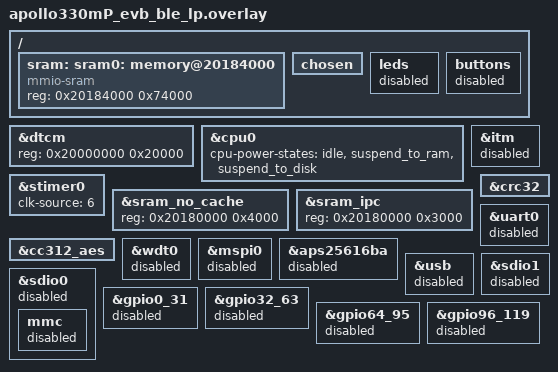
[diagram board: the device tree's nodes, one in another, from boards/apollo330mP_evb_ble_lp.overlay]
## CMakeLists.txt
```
# Copyright (c) 2026, Ambiq Micro Inc. <www.ambiq.com>
# SPDX-License-Identifier: Apache-2.0

cmake_minimum_required(VERSION 3.20.0)

find_package(Zephyr REQUIRED HINTS $ENV{ZEPHYR_BASE})

project(pm_peripheral_demo)

target_sources(app PRIVATE src/main.c)
```

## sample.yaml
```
sample:
  name: PM Peripheral Demo

tests:
  sample.boards.ambiq.pm_peripheral_demo:
    platform_allow:
      - apollo330mP_evb
      - apollo510dL_evb
    tags:
      - pm
      - bluetooth
      - flash
      - spi
      - i2c
      - crc
      - crypto
```

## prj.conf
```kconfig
# Logging
CONFIG_LOG=y

# BLE
CONFIG_BT=y
CONFIG_BT_PERIPHERAL=y
CONFIG_BT_DEVICE_NAME="Ambiq PM Demo"

# Flash
CONFIG_FLASH=y
CONFIG_FLASH_MAP=y

# SPI
CONFIG_SPI=y

# I2C
CONFIG_I2C=y

# Entropy (TRNG via zephyr,entropy = &trng in board chosen)
CONFIG_ENTROPY_GENERATOR=y

# CRC (hardware driver)
CONFIG_CRC=y

# Crypto (hardware CC312 AES via ambiq,crypto-aes DT node; driver auto-selected)
CONFIG_CRYPTO=y

# PM (already in board defconfig; kept here for portability)
CONFIG_PM=y
CONFIG_PM_DEVICE=y
CONFIG_PM_DEVICE_RUNTIME=y

CONFIG_MAIN_STACK_SIZE=4096
```

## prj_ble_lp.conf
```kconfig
CONFIG_BT=y
CONFIG_BT_SMP=y
CONFIG_BT_PERIPHERAL=y
CONFIG_BT_DIS=y
CONFIG_BT_DIS_PNP=n
CONFIG_BT_BAS=y
CONFIG_BT_HRS=y

CONFIG_BT_DEVICE_NAME="Ambiq PM Demo"
CONFIG_BT_DEVICE_APPEARANCE=833

# Recommended LP advertising interval for test setup.
# These preferred connection parameters reduce connected-mode radio wakeups.
CONFIG_BT_PERIPHERAL_PREF_MIN_INT=400
CONFIG_BT_PERIPHERAL_PREF_MAX_INT=480
CONFIG_BT_PERIPHERAL_PREF_LATENCY=4
CONFIG_BT_PERIPHERAL_PREF_TIMEOUT=3200

# CEVA/RSS 510L: RF trim IPC + RSS opmode + HCI 0xFC80 NVDS sleep + VS 0xFC82/0xFC83,
# then host HCI_Reset (see apollox_ipc_support.c).

# Match AmbiqSuite ble_freertos_fit_lp early SoC init (LFRC RTC, XTAL deepsleep, SRAM 0.75M retain,
# caches off, IOSFD..NETAOL-1 gating, NETAOL/RSS on). See CONFIG_SOC_AMBIQ_APOLLO5X_BLE_LP in soc/Kconfig.
# Enabling this option will further reduce power consumption in sleep modes, but with risk of stability.
# Disable this option if user experience stability issues.
CONFIG_SOC_AMBIQ_APOLLO5X_BLE_LP=y

CONFIG_LOG=n
CONFIG_BOOT_BANNER=n
CONFIG_PRINTK=n
CONFIG_EARLY_CONSOLE=n
CONFIG_CONSOLE=n
CONFIG_UART_CONSOLE=n

# Keep Ambiq HAL GPIO available for SoC clock code without enabling the sample LED path.
CONFIG_PINCTRL=y
CONFIG_GPIO=n
CONFIG_SPI=n
CONFIG_I2C=n
CONFIG_WATCHDOG=n

# Enable CRC32 hardware accelerator.
CONFIG_CRC=y

# Demo threads exercise storage_partition through Zephyr's flash map API.
CONFIG_FLASH=y
CONFIG_FLASH_MAP=y

# Enable entropy/TRNG for random number generation.
CONFIG_ENTROPY_GENERATOR=y

# Demo AES thread uses the Ambiq CC312 AES crypto device.
CONFIG_CRYPTO=y

CONFIG_PM=y
CONFIG_PM_DEVICE=y
CONFIG_PM_DEVICE_RUNTIME=y
CONFIG_PM_NEED_ALL_DEVICES_IDLE=y

# CPU idle: long timer slips + default policy choose suspend-to-idle / suspend-to-ram from DT.
CONFIG_TICKLESS_KERNEL=y
CONFIG_PM_POLICY_DEFAULT=y
```

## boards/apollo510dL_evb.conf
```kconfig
# The board chooses an enabled crc32 node and the SoC is APOLLO5X, so the
# Ambiq hardware CRC driver can be built. CRC_DRIVER is a menuconfig that
# defaults to n, so enable it here to exercise the CRC32 demo thread.
CONFIG_CRC_DRIVER=y
```

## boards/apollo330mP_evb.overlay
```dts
/*
 * Copyright (c) 2026, Ambiq Micro Inc. <www.ambiq.com>
 *
 * SPDX-License-Identifier: Apache-2.0
 */

/*
 * PM power states for apollo330mP_evb.
 * Three suspend-to-idle states are defined, matching the CPU power-down
 * levels supported by the Apollo330P SoC.
 */

/ {
	zephyr,user {
		k_idle_state_min_residency_time = <300>;
	};
};

&cpu0 {
	cpu-power-states = <&stop0 &stop1 &stop2>;
};

&{/cpus/power-states} {
	stop0: stop0 {
		compatible = "zephyr,power-state";
		power-state-name = "suspend-to-idle";
		substate-id = <1>;
		min-residency-us = <300>;
		exit-latency-us = <50>;
	};

	stop1: stop1 {
		compatible = "zephyr,power-state";
		power-state-name = "suspend-to-idle";
		substate-id = <2>;
		min-residency-us = <700>;
		exit-latency-us = <300>;
	};

	stop2: stop2 {
		compatible = "zephyr,power-state";
		power-state-name = "suspend-to-idle";
		substate-id = <3>;
		min-residency-us = <1000>;
		exit-latency-us = <400>;
	};
};

/* Enable SPI0 on IOM0 (pinctrl already defined in apollo330mP_evb-pinctrl.dtsi) */
&spi0 {
	status = "okay";
};

/* Enable I2C1 on IOM1 (separate IOM from spi0, pinctrl already defined) */
&i2c1 {
	status = "okay";
};

/* Enable hardware CC312 AES accelerator */
&cc312_aes {
	status = "okay";
};
```

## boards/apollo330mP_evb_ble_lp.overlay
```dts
/*
 * Copyright (c) 2026 Ambiq Micro Inc.
 *
 * SPDX-License-Identifier: Apache-2.0
 *
 * pm_peripheral_demo BLE low-power overlay for apollo330mP_evb.
 *
 * Apply with prj_ble_lp.conf for BLE-only low-power builds:
 *
 *   west build -b apollo330mP_evb samples/boards/ambiq/pm_peripheral_demo \\
 *     -- -DCONF_FILE=prj_ble_lp.conf \\
 *        -DDTC_OVERLAY_FILE=boards/apollo330mP_evb_ble_lp.overlay
 *
 * - SRAM at 0x20184000 (0x74000), DTCM 128 KiB; IPC shared SRAM starts at 0x20180000.
 * - CPU PM: idle, suspend_to_ram, suspend_to_disk (validate BLE IPC/RSS/HCI after wake).
 * - stimer0 clk-source 6 (LFRC) for tickless-friendly timekeeping.
 * - Disables UART console, GPIO banks, ITM/SWO, and other unused blocks; keep IPC/stimer for BLE.
 *
 * Active during advertising (sample needs): flash/MRAM, stimer, IPC+mbox (HCI), TRNG (entropy),
 * CC312 AES, CRC32, kernel tick/timer — not LEDs/buttons, UART, USB, SDIO, MSPI/PSRAM,
 * SPI, I2C, WDT, or GPIO blocks.
 * SoC: enable CONFIG_SOC_AMBIQ_APOLLO5X_BLE_LP (prj_ble_lp.conf) to align with AmbiqSuite
 * ble_freertos_fit_lp (LFRC RTC, XTAL pwdn in sleep, SRAM 0.75M retain, caches off, NETAOL kept).
 * SoC also powers down IOM/UART/MSPI/USB/SDIO/etc. so pads are not held active by those blocks
 * (BTDM RXEN/TXEN are still driven by the radio after bt_enable).
 */
&dtcm {
	reg = <0x20000000 0x20000>;
};

&cpu0 {
	cpu-power-states = <&idle &suspend_to_ram &suspend_to_disk>;
};

&stimer0 {
	clk-source = <6>;
};

/* SWO is unused with CONFIG_CONSOLE=n; drop pinmux so the trace pin can stay low-leakage. */
&itm {
	status = "disabled";
	/delete-property/ pinctrl-0;
	/delete-property/ pinctrl-names;
};

/delete-node/ &sram0;

/ {
	sram: sram0: memory@20184000 {
		compatible = "mmio-sram";
		reg = <0x20184000 0x74000>;
	};
};

&sram_no_cache {
	/* Reserve 16 KiB at SRAM base for nocache/IPC shared memory. */
	reg = <0x20180000 0x4000>;
};

&sram_ipc {
	/* Keep 12 KiB IPC buffer inside the reserved nocache shared window. */
	reg = <0x20180000 0x3000>;
};

/ {
	chosen {
		/delete-property/ zephyr,console;
		/delete-property/ zephyr,uart-mcumgr;
		/delete-property/ zephyr,shell-uart;
		/delete-property/ zephyr,uart-pipe;
	};

	leds {
		status = "disabled";
	};

	buttons {
		status = "disabled";
	};
};

/* Enable hardware accelerators needed by demo threads. */
&cc312_aes {
	status = "okay";
};

&crc32 {
	status = "okay";
};

&uart0 {
	status = "disabled";
};

&wdt0 {
	status = "disabled";
};

&mspi0 {
	status = "disabled";
};

&aps25616ba {
	status = "disabled";
};

&usb {
	status = "disabled";
};

&sdio0 {
	status = "disabled";

	mmc {
		status = "disabled";
	};
};

&sdio1 {
	status = "disabled";
};

&gpio0_31 {
	status = "disabled";
};

&gpio32_63 {
	status = "disabled";
};

&gpio64_95 {
	status = "disabled";
};

&gpio96_119 {
	status = "disabled";
};
```

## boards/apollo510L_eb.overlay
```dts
/*
 * Copyright (c) 2026, Ambiq Micro Inc. <www.ambiq.com>
 *
 * SPDX-License-Identifier: Apache-2.0
 */

&cpu0 {
	cpu-power-states = <&stop0 &stop1 &stop2>;
};

&{/cpus/power-states} {
	stop0: stop0 {
		compatible = "zephyr,power-state";
		power-state-name = "suspend-to-idle";
		substate-id = <1>;
		min-residency-us = <300>;
		exit-latency-us = <50>;
	};

	stop1: stop1 {
		compatible = "zephyr,power-state";
		power-state-name = "suspend-to-idle";
		substate-id = <2>;
		min-residency-us = <700>;
		exit-latency-us = <300>;
	};

	stop2: stop2 {
		compatible = "zephyr,power-state";
		power-state-name = "suspend-to-idle";
		substate-id = <3>;
		min-residency-us = <1000>;
		exit-latency-us = <400>;
	};
};

/* Enable hardware CC312 AES accelerator */
&cc312_aes {
	status = "okay";
};

/* apollo510L_eb has spi5 enabled in board DTS; add alias for the demo.
 * No IOM I2C is exposed on this board — the i2c demo is skipped.
 */
/* / {
 *	aliases {
 *		demo-spi = &spi5;
 *	};
 * };
 */
```

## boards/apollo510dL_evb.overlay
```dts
/*
 * Copyright (c) 2026, Ambiq Micro Inc. <www.ambiq.com>
 *
 * SPDX-License-Identifier: Apache-2.0
 */

&cpu0 {
	cpu-power-states = <&stop0 &stop1 &stop2>;
};

&{/cpus/power-states} {
	stop0: stop0 {
		compatible = "zephyr,power-state";
		power-state-name = "suspend-to-idle";
		substate-id = <1>;
		min-residency-us = <300>;
		exit-latency-us = <50>;
	};

	stop1: stop1 {
		compatible = "zephyr,power-state";
		power-state-name = "suspend-to-idle";
		substate-id = <2>;
		min-residency-us = <700>;
		exit-latency-us = <300>;
	};

	stop2: stop2 {
		compatible = "zephyr,power-state";
		power-state-name = "suspend-to-idle";
		substate-id = <3>;
		min-residency-us = <1000>;
		exit-latency-us = <400>;
	};
};

/* Enable hardware CC312 AES accelerator */
&cc312_aes {
	status = "okay";
};

/* Enable SPI0 on IOM0 */
&spi0 {
	status = "disabled";
};

/* Enable I2C0 on IOM0 — separate IOM from spi0 would need a different IOM;
 * apollo510dL_evb exposes i2c0 on IOM0 alongside spi0 (shared IOM, only one
 * can be active at a time).  Use i2c1 on IOM1 to keep them independent.
 */
&i2c1 {
	status = "disabled";
};

/* / {
 *	aliases {
 *		demo-spi = &spi0;
 *		demo-i2c = &i2c1;
 *	};
 * };
 */
```

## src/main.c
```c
/*
 * Copyright (c) 2026, Ambiq Micro Inc. <www.ambiq.com>
 *
 * SPDX-License-Identifier: Apache-2.0
 */

/**
 * @file
 * @brief PM Peripheral Demo — apollo330mP_evb
 *
 * Demonstrates PM-aware peripheral use on the Apollo330P SoC:
 *   - BLE: advertising as a connectable peripheral (IPC-based, no overlay)
 *   - Flash: erase / write / read on storage_partition
 *   - CRC32: hardware digest over flash read-back (ambiq,hw-crc32)
 *   - AES-128-ECB: hardware encrypt/decrypt via ARM CC312 AES accelerator
 *     (cc312_aes DT node, uses Ambiq HAL CC312 driver)
 *   - SPI: bus transfer on spi0 (IOM0)
 *   - I2C: bus scan on i2c1 (IOM1)
 *
 * Each peripheral runs in its own dedicated Zephyr thread.  Threads sleep
 * between iterations with staggered start times so the PM subsystem gets
 * varied idle windows and can exercise multiple suspend-to-idle substates.
 * When all threads are simultaneously idle, the deepest eligible power state
 * is entered and the system wakes via the next thread's timeout.
 */

#include <zephyr/kernel.h>
#include <zephyr/device.h>
#include <zephyr/drivers/flash.h>
#include <zephyr/drivers/spi.h>
#include <zephyr/drivers/i2c.h>
#include <zephyr/drivers/crc.h>
#include <zephyr/drivers/entropy.h>
#include <zephyr/storage/flash_map.h>
#include <zephyr/bluetooth/bluetooth.h>
#include <zephyr/bluetooth/hci.h>
#include <zephyr/crypto/crypto.h>
#include <string.h>

#include <zephyr/logging/log.h>
LOG_MODULE_REGISTER(pm_demo, CONFIG_LOG_DEFAULT_LEVEL);

/* ---- Device nodes ---- */
/*
 * The CRC demo needs both a chosen node and a CRC driver built for it.
 * DT_HAS_CHOSEN() alone is not enough: a board may choose an enabled
 * crc32 node whose driver cannot be selected (for example, CRC_AMBIQ
 * depends on SOC_SERIES_APOLLO5X), leaving DEVICE_DT_GET() unresolved.
 */
#if defined(CONFIG_CRC_DRIVER) && DT_HAS_CHOSEN(zephyr_crc)
#define CRC_NODE  DT_CHOSEN(zephyr_crc)
#define DEMO_HAS_CRC 1
#endif
#if DT_NODE_EXISTS(DT_ALIAS(demo_spi))
#define SPI_NODE DT_ALIAS(demo_spi)
#endif
#if DT_NODE_EXISTS(DT_ALIAS(demo_i2c))
#define I2C_NODE DT_ALIAS(demo_i2c)
#endif

/* Flash partition */
#define STORAGE_PART_ID FIXED_PARTITION_ID(storage_partition)

/*
 * Write block size on apollo330P is 32 bytes (board DTS override).
 * Erase block size is 2048 bytes.
 * Keep the demo buffer at 64 bytes (2 × write-block, well within one erase
 * block) so erase / write / read are all properly aligned.
 */
#define FLASH_DEMO_BUF_SIZE 64
#define FLASH_DEMO_ERASE_SIZE 2048

/* Per-thread period and staggered boot delay (ms).  Staggering prevents all
 * threads from waking simultaneously, giving PM more varied idle windows.
 */
#define DEMO_PERIOD_MS      15000
#define STAGGER_ENTROPY_MS   5000
#define STAGGER_FLASH_CRC_MS 2000
#define STAGGER_AES_MS       4000
#define STAGGER_SPI_MS       6000
#define STAGGER_I2C_MS       8000

/* ---- AES-128-ECB test vectors (FIPS 197, first vector) ---- */
static const uint8_t aes_key[16] __aligned(4) = {
	0x00, 0x01, 0x02, 0x03, 0x04, 0x05, 0x06, 0x07,
	0x08, 0x09, 0x0a, 0x0b, 0x0c, 0x0d, 0x0e, 0x0f,
};
static uint8_t aes_plaintext[16] __aligned(4) = {
	0x00, 0x11, 0x22, 0x33, 0x44, 0x55, 0x66, 0x77,
	0x88, 0x99, 0xaa, 0xbb, 0xcc, 0xdd, 0xee, 0xff,
};
static const uint8_t aes_expected_ct[16] __aligned(4) = {
	0x69, 0xc4, 0xe0, 0xd8, 0x6a, 0x7b, 0x04, 0x30,
	0xd8, 0xcd, 0xb7, 0x80, 0x70, 0xb4, 0xc5, 0x5a,
};

/* ---- Entropy demo buffer ---- */
#define ENTROPY_BUF_SIZE 16
static uint8_t entropy_buf[ENTROPY_BUF_SIZE];

/* ---- Flash demo buffers ---- */
static const uint8_t flash_write_buf[FLASH_DEMO_BUF_SIZE] = {
	'A', 'm', 'b', 'i', 'q', ' ', 'P', 'M', ' ', 'D', 'e', 'm', 'o', '!',
	0x01, 0x02, 0x03, 0x04, 0x05, 0x06, 0x07, 0x08,
	0x09, 0x0a, 0x0b, 0x0c, 0x0d, 0x0e, 0x0f, 0x10,
	0x11, 0x12, 0x13, 0x14, 0x15, 0x16, 0x17, 0x18,
	0x19, 0x1a, 0x1b, 0x1c, 0x1d, 0x1e, 0x1f, 0x20,
	0x21, 0x22, 0x23, 0x24, 0x25, 0x26, 0x27, 0x28,
	0x29, 0x2a, 0x2b, 0x2c, 0x2d, 0x2e, 0x2f, 0x30,
};
static uint8_t flash_read_buf[FLASH_DEMO_BUF_SIZE];

/* ---- SPI demo buffers ---- */
#if DT_NODE_EXISTS(DT_ALIAS(demo_spi))
static uint8_t spi_tx_buf[] = { 0xde, 0xad, 0xbe, 0xef };
static uint8_t spi_rx_buf[sizeof(spi_tx_buf)];
#endif

/* ---- BLE advertising data ---- */
static const struct bt_data ad[] = {
	BT_DATA_BYTES(BT_DATA_FLAGS, BT_LE_AD_GENERAL | BT_LE_AD_NO_BREDR),
	BT_DATA(BT_DATA_NAME_COMPLETE,
		CONFIG_BT_DEVICE_NAME,
		sizeof(CONFIG_BT_DEVICE_NAME) - 1),
};

/* Deferred work so bt_conn is fully released before we re-advertise. */
static void ble_adv_restart_work_handler(struct k_work *work)
{
	int ret;

	ret = bt_le_adv_start(BT_LE_ADV_CONN_FAST_1, ad, ARRAY_SIZE(ad), NULL, 0);
	if (ret) {
		LOG_ERR("bt_le_adv_start (reconnect): %d", ret);
	} else {
		LOG_INF("BLE: advertising as \"%s\"", CONFIG_BT_DEVICE_NAME);
	}
}

static K_WORK_DEFINE(ble_adv_restart_work, ble_adv_restart_work_handler);

static void ble_disconnected(struct bt_conn *conn, uint8_t reason)
{
	LOG_INF("BLE: disconnected (reason 0x%02x)", reason);
	k_work_submit(&ble_adv_restart_work);
}

BT_CONN_CB_DEFINE(conn_callbacks) = {
	.disconnected = ble_disconnected,
};

/* ================================================================
 * Entropy demo — collect random bytes from the hardware TRNG
 *                 (zephyr,entropy = &trng in board chosen)
 * ================================================================
 */
static int demo_thread_entropy(void)
{
	const struct device *dev = DEVICE_DT_GET(DT_CHOSEN(zephyr_entropy));
	int ret;

	if (!device_is_ready(dev)) {
		LOG_ERR("Entropy device not ready");
		return -ENODEV;
	}

	ret = entropy_get_entropy(dev, entropy_buf, sizeof(entropy_buf));
	if (ret) {
		LOG_ERR("entropy_get_entropy: %d", ret);
		return ret;
	}

	LOG_INF("Entropy (TRNG): "
		"%02x %02x %02x %02x %02x %02x %02x %02x "
		"%02x %02x %02x %02x %02x %02x %02x %02x",
		entropy_buf[0],  entropy_buf[1],  entropy_buf[2],  entropy_buf[3],
		entropy_buf[4],  entropy_buf[5],  entropy_buf[6],  entropy_buf[7],
		entropy_buf[8],  entropy_buf[9],  entropy_buf[10], entropy_buf[11],
		entropy_buf[12], entropy_buf[13], entropy_buf[14], entropy_buf[15]);
	return 0;
}

/* ================================================================
 * Flash demo — erase a sector, write a fixed pattern, read it back
 * ================================================================
 */
static int demo_thread_flash(void)
{
	const struct flash_area *fa;
	int ret;

	ret = flash_area_open(STORAGE_PART_ID, &fa);
	if (ret) {
		LOG_ERR("flash_area_open: %d", ret);
		return ret;
	}

	ret = flash_area_erase(fa, 0, FLASH_DEMO_ERASE_SIZE);
	if (ret) {
		LOG_ERR("flash_area_erase: %d", ret);
		goto out;
	}

	ret = flash_area_write(fa, 0, flash_write_buf, sizeof(flash_write_buf));
	if (ret) {
		LOG_ERR("flash_area_write: %d", ret);
		goto out;
	}

	ret = flash_area_read(fa, 0, flash_read_buf, sizeof(flash_read_buf));
	if (ret) {
		LOG_ERR("flash_area_read: %d", ret);
		goto out;
	}

	if (memcmp(flash_write_buf, flash_read_buf, sizeof(flash_write_buf)) == 0) {
		LOG_INF("Flash: write/read verified OK (%zu bytes)", sizeof(flash_write_buf));
	} else {
		LOG_ERR("Flash: data mismatch after read-back");
		ret = -EIO;
	}

out:
	flash_area_close(fa);
	return ret;
}

#if defined(DEMO_HAS_CRC)
/* ================================================================
 * CRC32 demo — hardware digest over flash read-back buffer
 * ================================================================
 */
static int demo_thread_crc32(void)
{
	const struct device *dev = DEVICE_DT_GET(CRC_NODE);
	struct crc_ctx ctx = {
		.type       = CRC32_IEEE,
		.polynomial = CRC32_IEEE_POLY,
		.seed       = CRC32_IEEE_INIT_VAL,
		.reversed   = (CRC_FLAG_REVERSE_INPUT | CRC_FLAG_REVERSE_OUTPUT),
	};
	int ret;

	if (!device_is_ready(dev)) {
		LOG_ERR("CRC device not ready");
		return -ENODEV;
	}

	ret = crc_begin(dev, &ctx);
	if (ret) {
		LOG_ERR("crc_begin: %d", ret);
		return ret;
	}

	ret = crc_update(dev, &ctx, flash_read_buf, sizeof(flash_read_buf));
	if (ret) {
		LOG_ERR("crc_update: %d", ret);
		return ret;
	}

	ret = crc_finish(dev, &ctx);
	if (ret) {
		LOG_ERR("crc_finish: %d", ret);
		return ret;
	}

	LOG_INF("CRC32 (hardware): result=0x%08x over %zu bytes",
		(uint32_t)ctx.result, sizeof(flash_read_buf));
	return 0;
}
#endif /* DEMO_HAS_CRC */

/* ================================================================
 * AES demo — hardware AES-128-ECB via ARM CC312 AES accelerator
 *            (cc312_aes DT node, Ambiq HAL CC312 crypto driver)
 * ================================================================
 */
static int demo_thread_aes(void)
{
	const struct device *dev = DEVICE_DT_GET(DT_NODELABEL(cc312_aes));
	struct cipher_ctx sess;
	struct cipher_pkt op;
	uint8_t encrypted[16] __aligned(4);
	uint8_t decrypted[16] __aligned(4);
	uint32_t cap_flags;
	int ret;

	if (!device_is_ready(dev)) {
		LOG_ERR("CC312 AES device not ready");
		return -ENODEV;
	}

	cap_flags = crypto_query_hwcaps(dev);
	if (!(cap_flags & CAP_RAW_KEY) || !(cap_flags & CAP_SYNC_OPS) ||
	    !(cap_flags & CAP_SEPARATE_IO_BUFS)) {
		LOG_ERR("Crypto device missing required caps (0x%08x)", cap_flags);
		return -ENOTSUP;
	}
	cap_flags = CAP_RAW_KEY | CAP_SYNC_OPS | CAP_SEPARATE_IO_BUFS;

	/* Encrypt */
	sess = (struct cipher_ctx){
		.keylen         = sizeof(aes_key),
		.key.bit_stream = aes_key,
		.flags          = cap_flags,
	};
	ret = cipher_begin_session(dev, &sess, CRYPTO_CIPHER_ALGO_AES,
				   CRYPTO_CIPHER_MODE_ECB,
				   CRYPTO_CIPHER_OP_ENCRYPT);
	if (ret) {
		LOG_ERR("cipher_begin_session (enc): %d", ret);
		return ret;
	}

	op = (struct cipher_pkt){
		.in_buf      = aes_plaintext,
		.in_len      = sizeof(aes_plaintext),
		.out_buf     = encrypted,
		.out_buf_max = sizeof(encrypted),
	};
	ret = cipher_block_op(&sess, &op);
	cipher_free_session(dev, &sess);
	if (ret) {
		LOG_ERR("cipher_block_op (enc): %d", ret);
		return ret;
	}

	if (memcmp(encrypted, aes_expected_ct, sizeof(aes_expected_ct)) == 0) {
		LOG_INF("AES-128-ECB (hw CC312): encrypt matches FIPS-197 vector");
	} else {
		LOG_WRN("AES-128-ECB (hw CC312): ciphertext mismatch vs FIPS-197");
	}

	/* Decrypt */
	sess = (struct cipher_ctx){
		.keylen         = sizeof(aes_key),
		.key.bit_stream = aes_key,
		.flags          = cap_flags,
	};
	ret = cipher_begin_session(dev, &sess, CRYPTO_CIPHER_ALGO_AES,
				   CRYPTO_CIPHER_MODE_ECB,
				   CRYPTO_CIPHER_OP_DECRYPT);
	if (ret) {
		LOG_ERR("cipher_begin_session (dec): %d", ret);
		return ret;
	}

	op = (struct cipher_pkt){
		.in_buf      = encrypted,
		.in_len      = sizeof(encrypted),
		.out_buf     = decrypted,
		.out_buf_max = sizeof(decrypted),
	};
	ret = cipher_block_op(&sess, &op);
	cipher_free_session(dev, &sess);
	if (ret) {
		LOG_ERR("cipher_block_op (dec): %d", ret);
		return ret;
	}

	if (memcmp(decrypted, aes_plaintext, sizeof(aes_plaintext)) == 0) {
		LOG_INF("AES-128-ECB (hw CC312): decrypt round-trip verified");
	} else {
		LOG_ERR("AES-128-ECB (hw CC312): decrypt mismatch");
	}

	return 0;
}

#if DT_NODE_EXISTS(DT_ALIAS(demo_spi))
/* ================================================================
 * SPI demo — single transfer via demo-spi alias
 * ================================================================
 */
static int demo_thread_spi(void)
{
	const struct device *spi = DEVICE_DT_GET(SPI_NODE);
	const struct spi_config cfg = {
		.frequency = 1000000U,
		.operation = SPI_WORD_SET(8) | SPI_OP_MODE_MASTER,
	};
	struct spi_buf tx_buf = { .buf = spi_tx_buf, .len = sizeof(spi_tx_buf) };
	struct spi_buf rx_buf = { .buf = spi_rx_buf, .len = sizeof(spi_rx_buf) };
	struct spi_buf_set tx_set = { .buffers = &tx_buf, .count = 1 };
	struct spi_buf_set rx_set = { .buffers = &rx_buf, .count = 1 };
	int ret;

	if (!device_is_ready(spi)) {
		LOG_ERR("SPI device not ready");
		return -ENODEV;
	}

	ret = spi_transceive(spi, &cfg, &tx_set, &rx_set);
	if (ret) {
		/* Expected without loopback hardware; driver / bus is exercised */
		LOG_WRN("SPI transceive: %d (no loopback device connected)", ret);
	} else {
		LOG_INF("SPI: transceive complete (0x%02x 0x%02x 0x%02x 0x%02x)",
			spi_rx_buf[0], spi_rx_buf[1],
			spi_rx_buf[2], spi_rx_buf[3]);
	}

	return 0;
}
#endif /* DT_NODE_EXISTS(DT_ALIAS(demo_spi)) */

#if DT_NODE_EXISTS(DT_ALIAS(demo_i2c))
/* ================================================================
 * I2C demo — bus scan via demo-i2c alias
 * ================================================================
 */
static int demo_thread_i2c(void)
{
	const struct device *i2c = DEVICE_DT_GET(I2C_NODE);
	uint8_t dummy;
	int found = 0;

	if (!device_is_ready(i2c)) {
		LOG_ERR("I2C device not ready");
		return -ENODEV;
	}

	LOG_INF("I2C: scanning bus 0x08..0x77 ...");
	for (uint8_t addr = 0x08U; addr < 0x78U; addr++) {
		if (i2c_read(i2c, &dummy, sizeof(dummy), addr) == 0) {
			LOG_INF("I2C: device found at 0x%02x", addr);
			found++;
		}
	}
	if (found == 0) {
		LOG_INF("I2C: no devices found (expected without external hardware)");
	} else {
		LOG_INF("I2C: scan complete, %d device(s) found", found);
	}

	return 0;
}
#endif /* DT_NODE_EXISTS(DT_ALIAS(demo_i2c)) */

/* ================================================================
 * Thread: entropy
 * ================================================================
 */
static void entropy_thread_fn(void *p1, void *p2, void *p3)
{
	ARG_UNUSED(p1); ARG_UNUSED(p2); ARG_UNUSED(p3);

	k_msleep(STAGGER_ENTROPY_MS);
	while (true) {
		demo_thread_entropy();
		k_msleep(DEMO_PERIOD_MS);
	}
}

/* ================================================================
 * Thread: flash + CRC32
 * CRC32 digests the flash read-back buffer, so both run in one thread
 * to avoid a mutex on flash_read_buf.
 * ================================================================
 */
static void flash_crc_thread_fn(void *p1, void *p2, void *p3)
{
	ARG_UNUSED(p1); ARG_UNUSED(p2); ARG_UNUSED(p3);

	k_msleep(STAGGER_FLASH_CRC_MS);
	while (true) {
		demo_thread_flash();
#if defined(DEMO_HAS_CRC)
		demo_thread_crc32();
#endif
		k_msleep(DEMO_PERIOD_MS);
	}
}

/* ================================================================
 * Thread: AES (software via mbedTLS shim)
 * ================================================================
 */
static void aes_thread_fn(void *p1, void *p2, void *p3)
{
	ARG_UNUSED(p1); ARG_UNUSED(p2); ARG_UNUSED(p3);

	k_msleep(STAGGER_AES_MS);
	while (true) {
		demo_thread_aes();
		k_msleep(DEMO_PERIOD_MS);
	}
}

#if DT_NODE_EXISTS(DT_ALIAS(demo_spi))
/* ================================================================
 * Thread: SPI
 * ================================================================
 */
static void spi_thread_fn(void *p1, void *p2, void *p3)
{
	ARG_UNUSED(p1); ARG_UNUSED(p2); ARG_UNUSED(p3);

	k_msleep(STAGGER_SPI_MS);
	while (true) {
		demo_thread_spi();
		k_msleep(DEMO_PERIOD_MS);
	}
}
#endif /* DT_NODE_EXISTS(DT_ALIAS(demo_spi)) */

#if DT_NODE_EXISTS(DT_ALIAS(demo_i2c))
/* ================================================================
 * Thread: I2C
 * ================================================================
 */
static void i2c_thread_fn(void *p1, void *p2, void *p3)
{
	ARG_UNUSED(p1); ARG_UNUSED(p2); ARG_UNUSED(p3);

	k_msleep(STAGGER_I2C_MS);
	while (true) {
		demo_thread_i2c();
		k_msleep(DEMO_PERIOD_MS);
	}
}
#endif /* DT_NODE_EXISTS(DT_ALIAS(demo_i2c)) */

/* Thread definitions — created at startup, run forever */
K_THREAD_DEFINE(entropy_tid,   512,  entropy_thread_fn,   NULL, NULL, NULL, 7, 0, 0);
K_THREAD_DEFINE(flash_crc_tid, 1024, flash_crc_thread_fn, NULL, NULL, NULL, 7, 0, 0);
K_THREAD_DEFINE(aes_tid,       1536, aes_thread_fn,       NULL, NULL, NULL, 7, 0, 0);
#if DT_NODE_EXISTS(DT_ALIAS(demo_spi))
K_THREAD_DEFINE(spi_tid,        512, spi_thread_fn,       NULL, NULL, NULL, 7, 0, 0);
#endif
#if DT_NODE_EXISTS(DT_ALIAS(demo_i2c))
K_THREAD_DEFINE(i2c_tid,        768, i2c_thread_fn,       NULL, NULL, NULL, 7, 0, 0);
#endif

/* ================================================================
 * Entry point — BLE init only; peripheral work runs in threads above
 * ================================================================
 */
int main(void)
{
	int ret;

	LOG_INF("=== PM Peripheral Demo ===");
	LOG_INF("Board: %s", CONFIG_BOARD);

	/* BLE — IPC transport, no board overlay required */
	ret = bt_enable(NULL);
	if (ret) {
		LOG_ERR("bt_enable: %d", ret);
		return ret;
	}

	ret = bt_le_adv_start(BT_LE_ADV_CONN_FAST_1, ad, ARRAY_SIZE(ad), NULL, 0);
	if (ret) {
		LOG_ERR("bt_le_adv_start: %d", ret);
		return ret;
	}

	LOG_INF("BLE: advertising as \"%s\"", CONFIG_BT_DEVICE_NAME);
	return 0;
}
```
